# STM32MP153 register map
File version: 1.4
CPU: CM4 r0p1, little endian, no MPU, FPU, 4 interrupt priority bits
Registers are 32-bit, read-write, reset 0x0 unless marked. A register's access mark holds for its fields unless they carry their own. Offsets are from the block's base; [hi:lo] are bit positions; {n}, {i} and the like mark numbered series.

## HASH1 — HASH register block
Base 0x54002000
Same registers: HASH2 0x4C002000
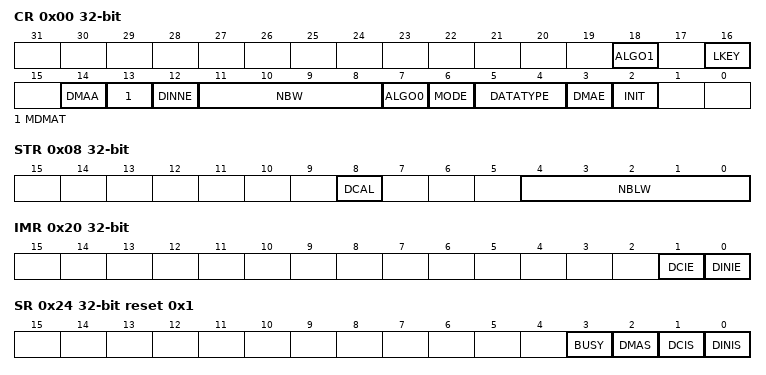
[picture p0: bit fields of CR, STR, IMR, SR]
0x00 CR access per field — HASH control register
  [18] ALGO1 rw, [16] LKEY rw, [14] DMAA wo, [13] MDMAT rw, [12] DINNE ro, [11:8] NBW ro, [7] ALGO0 rw, [6] MODE rw, [5:4] DATATYPE rw, [3] DMAE rw, [2] INIT wo
0x04 DIN — HASH_DIN is the data input register.
  [31:0] DATAIN
0x08 STR access per field — The HASH_STR register has two functions: It is used to define the number of valid bits in the last word of the message entered in the hash processor (that is the number of valid least significant bits in the last data written to the HASH_DIN register) It is used to start the processing of the last block in the message by writing the DCAL bit to 1
  [8] DCAL wo, [4:0] NBLW rw
{0xC+4i} HR{i} ro (i=0..4) — HASH digest register {i}
  [31:0] H{i}
0x20 IMR — HASH interrupt enable register
  [1] DCIE, [0] DINIE
0x24 SR access per field reset 0x1 — HASH status register
  [3] BUSY ro, [2] DMAS ro, [1] DCIS rw, [0] DINIS rw
0xF8 CSR0 reset 0x2 — These registers contain the complete internal register states of the hash processor. They are useful when a context swap has to be done because a high-priority task needs to use the hash processor while it is already used by another task. When such an event occurs, the HASH_CSRx registers have to be read and the read values have to be saved in the system memory space. Then the hash processor can be used by the preemptive task, and when the hash computation is complete, the saved context can be read from memory and written back into the HASH_CSRx registers.
  [31:0] CS0
{0xF8+4i} CSR{i} (i=1..53) — HASH context swap registers
  [31:0] CS{i}
{0x310+4i} HR{i} ro (i=5..7) — HASH digest register {i}
  [31:0] H{i}
0x3F0 HWCFGR ro reset 0x1 — HASH Hardware Configuration Register
  [3:0] CFG1
0x3F4 VERR ro reset 0x23 — HASH Version Register
  [7:0] VER
0x3F8 IPIDR ro reset 0x170031 — HASH Identification
  [31:0] ID
0x3FC MID ro reset 0xA3C5DD01 — HASH Hardware Magic ID

## HDMI_CEC
Base 0x40016000
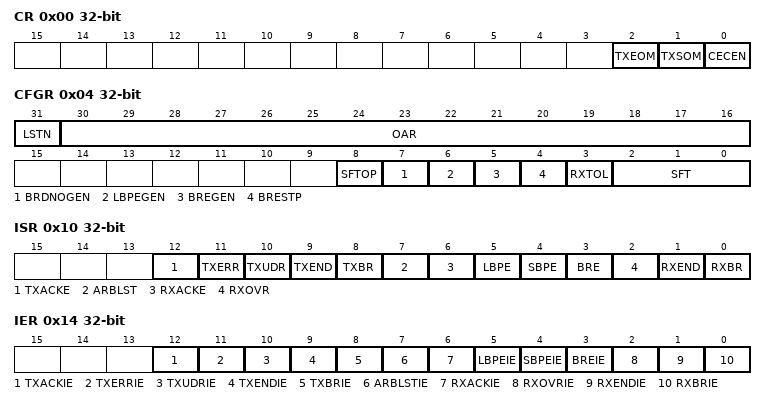
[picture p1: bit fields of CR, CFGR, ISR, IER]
0x00 CR — CEC control register
  [2] TXEOM, [1] TXSOM, [0] CECEN
0x04 CFGR — This register is used to configure the HDMI-CEC controller. It is mandatory to write CEC_CFGR only when CECEN=0.
  [31] LSTN, [30:16] OAR, [8] SFTOP, [7] BRDNOGEN, [6] LBPEGEN, [5] BREGEN, [4] BRESTP, [3] RXTOL, [2:0] SFT
0x08 TXDR — CEC Tx data register
  [7:0] TXD wo
0x0C RXDR ro — CEC Rx data register
  [7:0] RXD
0x10 ISR — CEC Interrupt and Status Register
  [12] TXACKE, [11] TXERR, [10] TXUDR, [9] TXEND, [8] TXBR, [7] ARBLST, [6] RXACKE, [5] LBPE, [4] SBPE, [3] BRE, [2] RXOVR, [1] RXEND, [0] RXBR
0x14 IER — CEC interrupt enable register
  [12] TXACKIE, [11] TXERRIE, [10] TXUDRIE, [9] TXENDIE, [8] TXBRIE, [7] ARBLSTIE, [6] RXACKIE, [5] LBPEIE, [4] SBPEIE, [3] BREIE, [2] RXOVRIE, [1] RXENDIE, [0] RXBRIE

## HDP
Base 0x5002A000
0x00 CTRL — HDP Control
  [0] EN
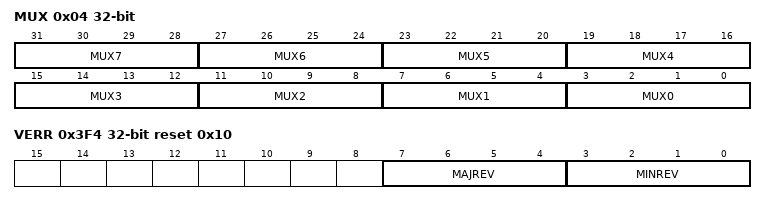
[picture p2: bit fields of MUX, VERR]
0x04 MUX — HDP multiplexing
  [4n+3:4n] MUX{n} (n=0..7)
0x10 VAL ro — HDP value
  [7:0] HDPVAL
0x14 GPOSET wo — HDP GPO set
  [7:0] HDPGPOSET
0x18 GPOCLR wo — HDP GPO clear
  [7:0] HDPGPOCLR
0x1C GPOVAL — HDP GPO value
  [7:0] HDPGPOVAL
0x3F4 VERR ro reset 0x10 — HDP version register
  [7:4] MAJREV, [3:0] MINREV
0x3F8 IPIDR ro reset 0x30002 — HDP IP identification register
  [31:0] ID
0x3FC SIDR ro reset 0xA3C5DD01 — HDP size identification register
  [31:0] SID

## HSEM
Base 0x4C000000
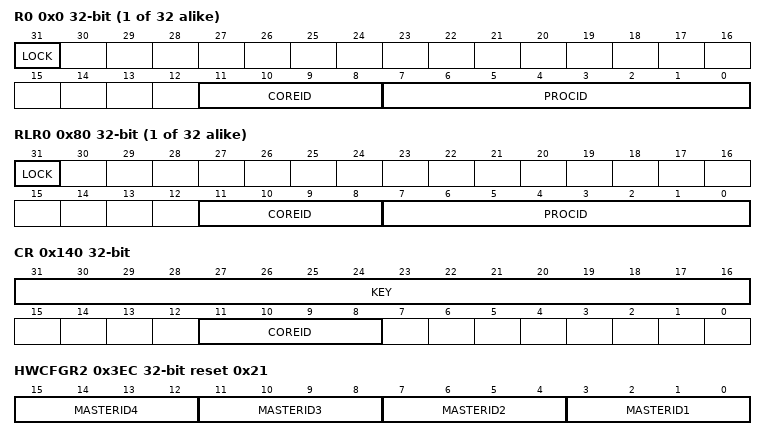
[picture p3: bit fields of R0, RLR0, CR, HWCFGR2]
{0x0+4i} R{i} (i=0..31) — The HSEM_Rx shall be used to perform a 2-step Write lock and Read back. Only Write accesses with authorized AHB bus master IDs are granted. Write accesses with unauthorized AHB bus master IDs are discarded.
  [31] LOCK, [11:8] COREID, [7:0] PROCID
{0x80+4i} RLR{i} ro (i=0..31) — Accesses the same physical bits as HSEM_Rx. The HSEM_RLRx shall be used to perform a 1-step Read lock. Only Read accesses with authorized AHB bus master IDs are granted. Read accesses with unauthorized AHB bus master IDs are discarded.
  [31] LOCK, [11:8] COREID, [7:0] PROCID
0x100 C1IER — HSEM i1terrupt enable register
  [31:0] ISE
0x104 C1ICR — HSEM i1terrupt clear register
  [31:0] ISC
0x108 C1ISR ro — HSEM i1terrupt status register
  [31:0] ISF
0x10C C1MISR ro — HSEM i1terrupt status register
  [31:0] MISF
0x110 C2IER — HSEM i2terrupt enable register
  [31:0] ISE
0x114 C2ICR — HSEM i2terrupt clear register
  [31:0] ISC
0x118 C2ISR ro — HSEM i2terrupt status register
  [31:0] ISF
0x11C C2MISR ro — HSEM i2terrupt status register
  [31:0] MISF
0x140 CR wo — Only Write accesses with authorized AHB bus master IDs are granted. Write accesses with unauthorized AHB bus master IDs are discarded.
  [31:16] KEY, [11:8] COREID
0x144 KEYR — HSEM interrupt clear register
  [31:16] KEY
0x3EC HWCFGR2 ro reset 0x21 — HSEM hardware configuration register 2
  [4n-1:4n-4] MASTERID{n} (n=1..4)
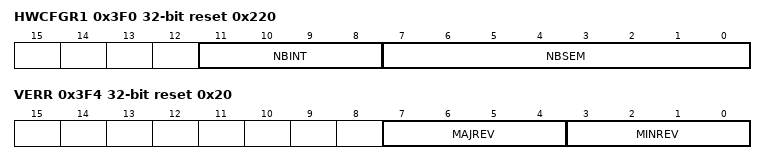
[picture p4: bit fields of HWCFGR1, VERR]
0x3F0 HWCFGR1 ro reset 0x220 — HSEM hardware configuration register 1
  [11:8] NBINT, [7:0] NBSEM
0x3F4 VERR ro reset 0x20 — HSEM IP version register
  [7:4] MAJREV, [3:0] MINREV
0x3F8 IPIDR ro reset 0x100072 — HSEM IP identification register
  [31:0] IPID
0x3FC SIDR ro reset 0xA3C5DD01 — HSEM size identification register
  [31:0] SID
